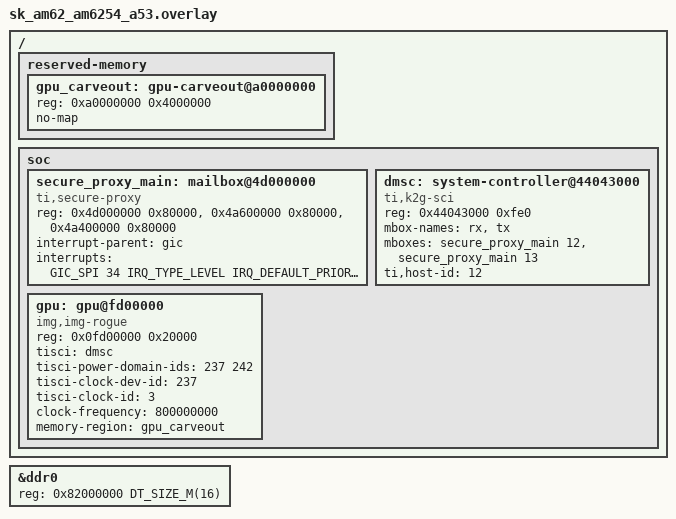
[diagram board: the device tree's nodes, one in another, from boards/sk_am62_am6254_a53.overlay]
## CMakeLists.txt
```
# SPDX-License-Identifier: Apache-2.0
# SPDX-FileCopyrightText: 2026 Signal Slot, Inc.
cmake_minimum_required(VERSION 3.20.0)

# The driver (driver/) and YakoGL (the repository root) are Zephyr modules;
# point ZEPHYR_EXTRA_MODULES at both unless a west manifest lists them.
get_filename_component(PVR_REPO "${CMAKE_CURRENT_SOURCE_DIR}/../../.." ABSOLUTE)
include("${CMAKE_CURRENT_SOURCE_DIR}/../common/yakogl_dir.cmake")

find_package(Zephyr REQUIRED HINTS $ENV{ZEPHYR_BASE})
project(gl_triangle)

target_sources(app PRIVATE src/main.c)
include("${CMAKE_CURRENT_SOURCE_DIR}/../common/sample.cmake")
```

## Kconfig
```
# SPDX-License-Identifier: Apache-2.0
# SPDX-FileCopyrightText: 2026 Signal Slot, Inc.
# Where gl_triangle draws and what it does afterwards.

# The in-process shader compiler (CONFIG_YAKOGL_SHADERC_ONLINE) runs on the
# thread that calls glCompileShader, here main, and needs about 74 KiB of stack
# on the PowerVR build (host measurement). With 64 KiB it overflowed into the
# idle threads' stacks, which sit right below main's in .bss, and the next
# switch to idle faulted at ELR 0x0/0x2; 256 KiB ran clean (AM62P, 2026-09-23).
# So the online build gets 256 KiB; the table build keeps its old size.
config MAIN_STACK_SIZE
	default 262144 if YAKOGL_SHADERC_ONLINE
	default 32768

menu "gl_triangle"

config GL_TRIANGLE_WINDOW_PHYS
	hex "Physical address of the window buffer (0 = a buffer in the image)"
	default 0
	help
	  Set this to a panel's scan-out buffer to draw on the display, e.g.
	  the framebuffer the previous OS left behind. 0 renders into a small
	  RGBA8888 buffer owned by the program and only reads pixels back.

config GL_TRIANGLE_WINDOW_WIDTH
	int "Window width in pixels"
	default 64

config GL_TRIANGLE_WINDOW_HEIGHT
	int "Window height in pixels"
	default 64

config GL_TRIANGLE_WINDOW_STRIDE
	int "Window row pitch in bytes (0 = width * 4)"
	default 0

endmenu

rsource "../common/Kconfig"
source "Kconfig.zephyr"
```

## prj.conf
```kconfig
# SPDX-License-Identifier: Apache-2.0
# SPDX-FileCopyrightText: 2026 Signal Slot, Inc.
CONFIG_SAFEUI_GPU_PVR=y
CONFIG_YAKOGL=y

CONFIG_LOG=y
CONFIG_LOG_MODE_IMMEDIATE=y
CONFIG_FPU=y
CONFIG_CACHE_MANAGEMENT=y

# glShaderSource keeps a copy of the source (malloc); the GL core runs on the
# main thread (its per-draw scratch is static, but keep headroom).
CONFIG_COMMON_LIBC_MALLOC_ARENA_SIZE=131072
# CONFIG_MAIN_STACK_SIZE: see Kconfig (256 KiB with the online compiler).

# A stack overflow must fault where it happens, not in another thread later.
# The A53 has no MPU, so HW_STACK_PROTECTION is not available on arm64 Cortex-A
# (ARM64_STACK_PROTECTION depends on ARM_MPU); the sentinel checks the lowest
# stack word at every context switch. A large frame can step over it, so it
# narrows the blind spot rather than closing it.
CONFIG_STACK_SENTINEL=y

# crc32_ieee for the shared PICTURE record line.
CONFIG_CRC=y
```

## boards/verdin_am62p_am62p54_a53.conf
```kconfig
# SPDX-License-Identifier: Apache-2.0
# SPDX-FileCopyrightText: 2026 Signal Slot, Inc.
# Verdin AM62P entered from Torizon Linux with tools/kexec-zephyr: bring the
# DSI panel up with the SafeUI display drivers, draw into a full-screen
# XRGB8888 buffer in the image and show it as the DSS application plane,
# keep it for the camera, then reset back into Linux.
CONFIG_GL_TRIANGLE_WINDOW_PHYS=0
CONFIG_GL_TRIANGLE_WINDOW_WIDTH=1024
CONFIG_GL_TRIANGLE_WINDOW_HEIGHT=600
CONFIG_PVR_SAMPLE_HOLD_SECONDS=40
CONFIG_PVR_SAMPLE_REBOOT=y
CONFIG_REBOOT=y
# The RTI watchdog Linux leaves running (kexec entry): fed for 150 s, then a
# hung image is reset by it.
CONFIG_SOC_AM62PX_A53_FEED_INHERITED_WDT=y
# The bound, for whichever feeder runs (common/Kconfig).
CONFIG_YAKOGL_AM62P_WDT_SECONDS=150

# Init order: mailbox 40 -> TISCI 45 -> TISCI power-on 46 -> GPIO 47 ->
# I2C 50 -> DSI 70 -> DSS 80 -> GPU 90 -> panel bridge 95.
CONFIG_MBOX=y
CONFIG_MBOX_TI_SECURE_PROXY=y
CONFIG_TISCI=y
CONFIG_TISCI_INIT_PRIORITY=45
CONFIG_GPIO_INIT_PRIORITY=47
CONFIG_SAFEUI_SN65DSI8X_SELF_START_INIT_PRIORITY=95

# Console on main_uart0 (Verdin UART_3, the X18 debug USB); DDR does not
# survive the reset, so a RAM console would be useless.
CONFIG_LOG_MODE_MINIMAL=y
# Bring-up knobs, off by default: CONFIG_PVR_SAMPLE_BOOT_TRACE=y prints a line
# per init priority band, CONFIG_SAFEUI_GPU_PVR_RENDER_VERBOSE=y dumps the render
# service's diagnostics after every frame.
```

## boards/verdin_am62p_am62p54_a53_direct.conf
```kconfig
# Verdin AM62P started by the A53 SPL at power-on, in place of U-Boot proper
# (docs/direct-boot.md). The board's devicetree has the display path on, so
# there is no overlay: bring the DSI panel up from cold, draw, show the
# window, keep it for the camera, then reset, which boots this image again
# (each reset is another boot-time sample).
CONFIG_GL_TRIANGLE_WINDOW_PHYS=0
CONFIG_GL_TRIANGLE_WINDOW_WIDTH=1024
CONFIG_GL_TRIANGLE_WINDOW_HEIGHT=600
CONFIG_PVR_SAMPLE_HOLD_SECONDS=40
CONFIG_PVR_SAMPLE_REBOOT=y
CONFIG_REBOOT=y
# The time since the R5 SPL started the GTC, at main() and at the first frame.
CONFIG_PVR_SAMPLE_BOOT_TIME=y

# Nothing started the RTI watchdog on this route: arm it here and feed it for
# 150 s, so a hung image is reset by it (after its 60 s period).
CONFIG_YAKOGL_AM62P_WDT_SECONDS=150
CONFIG_YAKOGL_AM62P_RTI_SELF_ARM=y

# Init order: mailbox 40 -> TISCI 45 -> TISCI power-on 46 -> GPIO 47 ->
# RTI arm 47 -> I2C 50 -> DSI 70 -> DSS 80 -> GPU 90 -> panel bridge 95.
CONFIG_MBOX=y
CONFIG_MBOX_TI_SECURE_PROXY=y
CONFIG_TISCI=y
CONFIG_TISCI_INIT_PRIORITY=45
CONFIG_GPIO_INIT_PRIORITY=47
CONFIG_SAFEUI_SN65DSI8X_SELF_START_INIT_PRIORITY=95

# Console on main_uart0 (Verdin UART_3, the X18 debug USB), the UART the SPLs
# print on.
CONFIG_LOG_MODE_MINIMAL=y
```

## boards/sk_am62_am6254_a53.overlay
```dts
/* SPDX-License-Identifier: Apache-2.0 */
/* SPDX-FileCopyrightText: 2026 Signal Slot, Inc. */
/*
 * The AM62P GPU for a TI K3 A53 target. Register block, TISCI ids and the
 * clock are the AM62P's (see
 * docs/notes/pvr-bringup-spec.md); the
 * carveout is a reserved 64 MiB of DDR that the Zephyr image and every
 * other user (R5F, OP-TEE, shared memory) leave alone. The dmsc/secure-proxy nodes are
 * the A53's TISCI channel (host id 12).
 */

#include <zephyr/dt-bindings/interrupt-controller/arm-gic.h>

/ {
	reserved-memory {
		#address-cells = <1>;
		#size-cells = <1>;
		ranges;

		gpu_carveout: gpu-carveout@a0000000 {
			reg = <0xa0000000 0x4000000>;
			no-map;
		};
	};

	soc {
		secure_proxy_main: mailbox@4d000000 {
			compatible = "ti,secure-proxy";
			reg-names = "target_data", "rt", "scfg";
			reg = <0x4d000000 0x80000>, <0x4a600000 0x80000>, <0x4a400000 0x80000>;
			interrupt-parent = <&gic>;
			interrupts = <GIC_SPI 34 IRQ_TYPE_LEVEL IRQ_DEFAULT_PRIORITY>;
			interrupt-names = "rx_012";
			#mbox-cells = <1>;
			status = "okay";
		};

		dmsc: system-controller@44043000 {
			compatible = "ti,k2g-sci";
			reg-names = "debug_messages";
			reg = <0x44043000 0xfe0>;
			mbox-names = "rx", "tx";
			mboxes = <&secure_proxy_main 12>, <&secure_proxy_main 13>;
			ti,host-id = <12>;
			status = "okay";
		};

		gpu: gpu@fd00000 {
			compatible = "img,img-rogue";
			reg = <0x0fd00000 0x20000>;
			tisci = <&dmsc>;
			tisci-power-domain-ids = <237 242>;
			tisci-clock-dev-id = <237>;
			tisci-clock-id = <3>;
			clock-frequency = <800000000>;
			memory-region = <&gpu_carveout>;
			status = "okay";
		};
	};
};

/* the Zephyr image: room for the firmware blob and the GL tables */
&ddr0 {
	reg = <0x82000000 DT_SIZE_M(16)>;
};
```

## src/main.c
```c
/* SPDX-License-Identifier: Apache-2.0 */
/* SPDX-FileCopyrightText: 2026 Signal Slot, Inc. */
/*
 * gl_triangle - the smallest YakoGL application: EGL window surface over a
 * pixel buffer this program owns, one Gouraud triangle, read back through
 * glReadPixels. The same source draws on the LVDS panel when the window's
 * physical address is the scan-out buffer.
 */
#include <zephyr/kernel.h>
#include <zephyr/sys/crc.h>
#include <zephyr/logging/log.h>
#include <zephyr/cache.h>
#include <EGL/egl.h>
#include <GLES2/gl2.h>
#include <gles_offline.h>
#include <string.h>
#include "sample_glue.h"

LOG_MODULE_REGISTER(gl_triangle, LOG_LEVEL_INF);

#define FB_W CONFIG_GL_TRIANGLE_WINDOW_WIDTH
#define FB_H CONFIG_GL_TRIANGLE_WINDOW_HEIGHT

#if CONFIG_GL_TRIANGLE_WINDOW_PHYS == 0
/* The window: a tightly packed buffer in the image. Zephyr's kernel memory
 * is identity mapped on this target, so its address is its physical address.
 * The GPU (and the display) read and write it directly, so it is not zeroed
 * by the boot code (__noinit) and the CPU cleans its cache lines before use.
 * XRGB8888 when a display scans it out, RGBA8888 for the read-back only case. */
static uint8_t s_fb[FB_W * FB_H * 4] __noinit __aligned(4096);
#define FB_PHYS   ((uintptr_t)s_fb)
#define FB_STRIDE (FB_W * 4)
#ifdef CONFIG_PVR_SAMPLE_SHOW_ON_DSS
#define FB_FORMAT GLES_NATIVE_FORMAT_XRGB8888
#else
#define FB_FORMAT GLES_NATIVE_FORMAT_RGBA8888
#endif
#else
/* A scan-out buffer (XRGB8888 rows) that the display keeps showing. */
#define FB_PHYS   ((uintptr_t)CONFIG_GL_TRIANGLE_WINDOW_PHYS)
#define FB_STRIDE (CONFIG_GL_TRIANGLE_WINDOW_STRIDE ? CONFIG_GL_TRIANGLE_WINDOW_STRIDE : FB_W * 4)
#define FB_FORMAT GLES_NATIVE_FORMAT_XRGB8888
#endif
/* the window is drawn y-up when the display scans it bottom row first */
#define WIN_FORMAT (FB_FORMAT | pvr_sample_window_flags())

#ifdef CONFIG_YAKOGL_SHADERC_ONLINE
/* The in-process compiler (the default back end) compiles GLSL ES, so the
 * sample hands it the ES 1.00 twins of the two shaders, byte for byte
 * tools/shaders/gl_test_es100/passthrough.vert and interp_color.frag (the
 * table's own texts are #version 450, which only Mesa compiled). A
 * measurement image that links the Mesa reference as its table
 * (CONFIG_YAKOGL_SHADERC_OFFLINE) takes the table's texts by name instead. */
static const char es100_vs_src[] =
	"#version 100\n"
	"/* Passthrough VS: position + one colour varying. ES 1.00 twin of\n"
	" * gl_test_passthrough_vs_src. Declaration order is the twin's location\n"
	" * order (a_pos 0, a_color 1). */\n"
	"attribute vec4 a_pos;\n"
	"attribute vec4 a_color;\n"
	"varying vec4 v_color;\n"
	"void main() {\n"
	"    gl_Position = a_pos;\n"
	"    v_color = a_color;\n"
	"}\n";

static const char es100_fs_src[] =
	"#version 100\n"
	"/* Interpolated-colour FS: consumes the passthrough VS's v_color varying.\n"
	" * ES 1.00 twin of gl_test_interp_fs_src. */\n"
	"precision mediump float;\n"
	"varying vec4 v_color;\n"
	"void main() { gl_FragColor = v_color; }\n";
#endif

/* The offline shader table only accepts the GLSL it was built from, byte for
 * byte; the library hands the text out by name (passthrough.vert: position +
 * colour through, interp_color.frag: the interpolated colour). */
static GLuint build_program(void)
{
	GLuint vs = glCreateShader(GL_VERTEX_SHADER), fs = glCreateShader(GL_FRAGMENT_SHADER);
	GLuint prog = glCreateProgram();
#ifdef CONFIG_YAKOGL_SHADERC_ONLINE
	const char *v = es100_vs_src;
	const char *f = es100_fs_src;
#else
	const char *v = gles_offline_shader_source("passthrough.vert");
	const char *f = gles_offline_shader_source("interp_color.frag");
#endif
	GLint ok = 0;

	if (!v || !f) {
		LOG_ERR("shader sources missing from the Mesa reference table");
		return 0;
	}

	glShaderSource(vs, 1, &v, NULL);
	glCompileShader(vs);
	glShaderSource(fs, 1, &f, NULL);
	glCompileShader(fs);
	glAttachShader(prog, vs);
	glAttachShader(prog, fs);
	glLinkProgram(prog);
	glGetProgramiv(prog, GL_LINK_STATUS, &ok);
	if (!ok) {
		char log[128];

		glGetProgramInfoLog(prog, sizeof(log), NULL, log);
		LOG_ERR("link failed: %s", log);
		return 0;
	}
	return prog;
}

#if CONFIG_GL_TRIANGLE_WINDOW_PHYS == 0
static void fill_pattern(void)
{
	uint32_t *px = (uint32_t *)s_fb;

	for (int y = 0; y < FB_H; y++) {
		uint32_t c = y < FB_H / 12 ? 0x00ffffffu : 0x00102040u;

		for (int x = 0; x < FB_W; x++) {
			px[y * FB_W + x] = c;
		}
	}
}
#endif

static int draw(void)
{
	static const EGLint cfg_attribs[] = {
		EGL_RED_SIZE, 8, EGL_GREEN_SIZE, 8, EGL_BLUE_SIZE, 8, EGL_ALPHA_SIZE, 8,
		EGL_DEPTH_SIZE, 16, EGL_SURFACE_TYPE, EGL_WINDOW_BIT,
		EGL_RENDERABLE_TYPE, EGL_OPENGL_ES2_BIT, EGL_NONE,
	};
	static const EGLint ctx_attribs[] = { EGL_CONTEXT_CLIENT_VERSION, 2, EGL_NONE };
	static const float verts[3][8] = {
		/* x, y, z, w,  r, g, b, a */
		{  0.0f,  0.8f, 0.0f, 1.0f, 1.0f, 0.0f, 0.0f, 1.0f },
		{ -0.8f, -0.8f, 0.0f, 1.0f, 0.0f, 1.0f, 0.0f, 1.0f },
		{  0.8f, -0.8f, 0.0f, 1.0f, 0.0f, 0.0f, 1.0f, 1.0f },
	};
	struct gles_native_window win = {
		.phys = FB_PHYS, .width = FB_W, .height = FB_H,
		.stride_bytes = FB_STRIDE, .format = WIN_FORMAT,
	};
	EGLDisplay dpy = eglGetDisplay(EGL_DEFAULT_DISPLAY);
	EGLConfig cfg;
	EGLSurface surf;
	EGLContext ctx;
	EGLint n = 0;
	GLuint prog, vbo;
	uint8_t px[4] = { 0, 0, 0, 0 };

	if (!eglInitialize(dpy, NULL, NULL) || !eglChooseConfig(dpy, cfg_attribs, &cfg, 1, &n) || n != 1) {
		LOG_ERR("EGL init failed: 0x%x", eglGetError());
		return 1;
	}
	surf = eglCreateWindowSurface(dpy, cfg, &win, NULL);
	ctx = eglCreateContext(dpy, cfg, EGL_NO_CONTEXT, ctx_attribs);
	if (surf == EGL_NO_SURFACE || ctx == EGL_NO_CONTEXT || !eglMakeCurrent(dpy, surf, surf, ctx)) {
		LOG_ERR("EGL surface/context failed: 0x%x", eglGetError());
		return 1;
	}

	prog = build_program();
	if (!prog) {
		return 1;
	}
	glUseProgram(prog);
	glGenBuffers(1, &vbo);
	glBindBuffer(GL_ARRAY_BUFFER, vbo);
	glBufferData(GL_ARRAY_BUFFER, sizeof(verts), verts, GL_STATIC_DRAW);
	glVertexAttribPointer(0, 4, GL_FLOAT, GL_FALSE, 32, (const void *)0);
	glVertexAttribPointer(1, 4, GL_FLOAT, GL_FALSE, 32, (const void *)16);
	glEnableVertexAttribArray(0);
	glEnableVertexAttribArray(1);

	glViewport(0, 0, FB_W, FB_H);
	glClearColor(0.0f, 0.0f, 0.0f, 1.0f);
	glClear(GL_COLOR_BUFFER_BIT);
	glDrawArrays(GL_TRIANGLES, 0, 3);
	eglSwapBuffers(dpy, surf);

	/* The centre is (W/2, H/2) in GL rows, the definition the i.MX8MP's
	 * gc_gl_triangle uses; this read (W/2, H/3) until 2026-09-23, so the two
	 * boards' "centre" were different pixels. */
	glReadPixels(FB_W / 2, FB_H / 2, 1, 1, GL_RGBA, GL_UNSIGNED_BYTE, px);
	LOG_INF("triangle drawn; centre pixel r=%u g=%u b=%u a=%u (GL error 0x%x)",
		px[0], px[1], px[2], px[3], glGetError());
	{
		/* The shared PICTURE record (kind 4), the same words gc_gl_triangle
		 * emits: w1 the centre pixel as glReadPixels returns it read as a
		 * little-endian word, w2 CRC-32/IEEE over the RGBA of the column
		 * samples at y = i*H/24 for i = 3..21 (inside the triangle, so
		 * independent of the clear colour), w3 W<<16 | H. */
		uint8_t col[19 * 4];
		uint32_t w1 = px[0] | px[1] << 8 | px[2] << 16 | (uint32_t)px[3] << 24;

		for (int i = 3; i <= 21; i++) {
			glReadPixels(FB_W / 2, (i * FB_H) / 24, 1, 1, GL_RGBA, GL_UNSIGNED_BYTE,
				     &col[(i - 3) * 4]);
		}
		LOG_INF("gl_triangle: record %08x %08x %08x %08x", 0x594b0400u, w1,
			crc32_ieee(col, sizeof(col)), (uint32_t)(FB_W << 16 | FB_H));
	}
	/* One column of samples, top to bottom: shows which rows the GPU wrote. */
	for (int y = 0; y < FB_H; y += FB_H / 24) {
		glReadPixels(FB_W / 2, y, 1, 1, GL_RGBA, GL_UNSIGNED_BYTE, px);
		LOG_INF("  row %3d: %02x%02x%02x", y, px[0], px[1], px[2]);
	}
	return 0;
}

int main(void)
{
	int rc;

	LOG_INF("gl_triangle: %ux%u window at 0x%lx", FB_W, FB_H, (unsigned long)FB_PHYS);
#if CONFIG_GL_TRIANGLE_WINDOW_PHYS == 0
	/* Start from a CPU-drawn pattern (dark blue, a white bar at the top) so
	 * the display path can be judged even when the GPU draw fails; the GPU
	 * overwrites it. */
	fill_pattern();
	sys_cache_data_flush_and_invd_range(s_fb, sizeof(s_fb));
#endif
	rc = draw();
	LOG_INF("gl_triangle: %s", rc ? "FAILED" : "done");
	/* Shown even after a failed draw: the pattern tells the display path apart. */
	if (pvr_sample_show_window(FB_PHYS, FB_W, FB_H, FB_STRIDE, WIN_FORMAT) && rc == 0) {
		rc = -EIO;
	}
	return pvr_sample_finish(rc);
}
```
